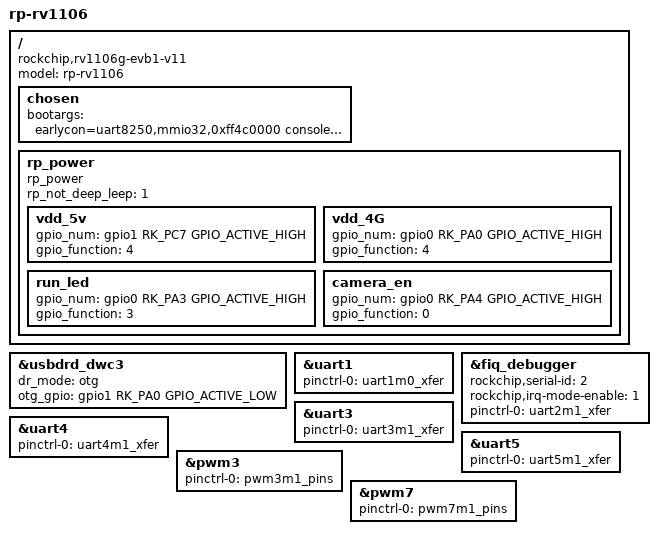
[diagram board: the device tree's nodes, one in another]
// SPDX-License-Identifier: (GPL-2.0+ OR MIT)
/*
 * Copyright (c) 2022 Rockchip Electronics Co., Ltd.
 */

/dts-v1/;

#include "rv1106-board.dtsi"

#include "rp-rtc-hym8563.dtsi"
#include "rp-spi2can-mcp2515.dtsi"
#include "rp-sdcard-mmc1.dtsi"
#include "rp-emmc-mmc0-4bit.dtsi"
#include "rp-sound.dtsi"
#include "rp-wifi-sdio.dtsi"
#include "rp-bt-uart0.dtsi"

#include "rp-mipi-camera-gc2093x2.dtsi"
//#include "rp-camera-gc2093x1.dtsi"

/ {
    model = "rp-rv1106";
    compatible = "rockchip,rv1106g-evb1-v11", "rockchip,rv1106";
    chosen {
        bootargs = "earlycon=uart8250,mmio32,0xff4c0000 console=ttyFIQ0 root=/dev/mmcblk0p5 rootfstype=ext4 rootwait snd_soc_core.prealloc_buffer_size_kbytes=16 coherent_pool=0";
    };
    
    rp_power{
        status = "okay";
        compatible = "rp_power";
        rp_not_deep_leep = <1>;

        //#define GPIO_FUNCTION_OUTPUT 0
        //#define GPIO_FUNCTION_INPUT 1
        //#define GPIO_FUNCTION_IRQ 2
        //#define GPIO_FUNCTION_FLASH 3
        //#define GPIO_FUNCTION_OUTPUT_CTRL 4

        vdd_5v{
            gpio_num = <&gpio1 RK_PC7 GPIO_ACTIVE_HIGH>;
            gpio_function = <4>;
        };
        
        vdd_4G{
            gpio_num = <&gpio0 RK_PA0 GPIO_ACTIVE_HIGH>;
            gpio_function = <4>;
        };
        
        run_led{
            gpio_num = <&gpio0 RK_PA3 GPIO_ACTIVE_HIGH>;
            gpio_function = <3>;
        };
        
        camera_en {
            gpio_num = <&gpio0 RK_PA4 GPIO_ACTIVE_HIGH>;
            gpio_function = <0>;
        };
    };
};

&usbdrd_dwc3 {
    //otg mode switch to host in /etc/init.d/S99_otg_def_host
    dr_mode = "otg";
    
    //Implemented by rpdzkj and implemented in kernel/drivers/usb/dwc3/core.c file.
    //when switch to host mode, otg_gpio pull up
    //when switch to device mode, otg_gpio pull down
    otg_gpio = <&gpio1 RK_PA0 GPIO_ACTIVE_LOW>;
};

//TTL
&uart1 {
    status = "okay";
    pinctrl-names = "default";
    pinctrl-0 = <&uart1m0_xfer>;
};

//debug uart2
&fiq_debugger {
    rockchip,serial-id = <2>;
    rockchip,irq-mode-enable = <1>;
    pinctrl-names = "default";
    pinctrl-0 = <&uart2m1_xfer>;
    status = "okay";
};

//rs485
&uart3 {
    status = "okay";
    pinctrl-names = "default";
    pinctrl-0 = <&uart3m1_xfer>;
};

//rs232
&uart4 {
    status = "okay";
    pinctrl-names = "default";
    pinctrl-0 = <&uart4m1_xfer>;
};

//rs232
&uart5 {
    status = "okay";
    pinctrl-names = "default";
    pinctrl-0 = <&uart5m1_xfer>;
};

&pwm3 {
    pinctrl-names = "active";
    pinctrl-0 = <&pwm3m1_pins>;
    status = "okay";
};

&pwm7 {
    pinctrl-names = "active";
    pinctrl-0 = <&pwm7m1_pins>;
    status = "okay";
};
